AUTOSAR XML (schema 4-0-3)
package /ComponentTypes
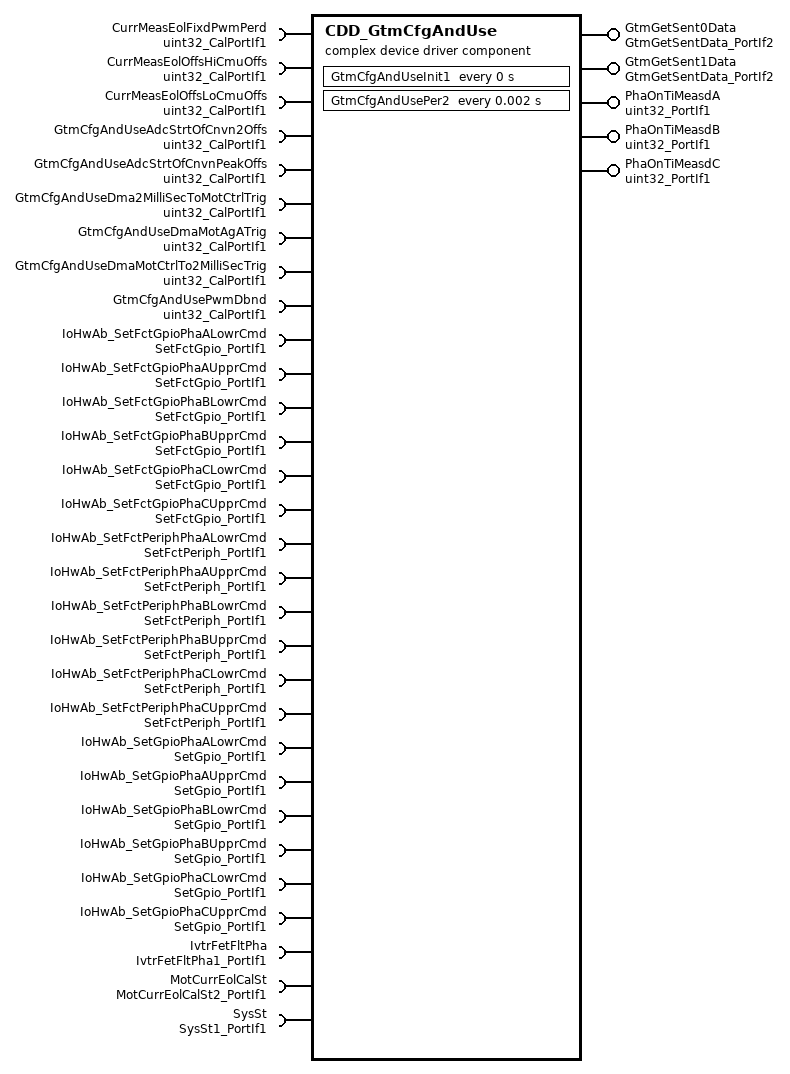
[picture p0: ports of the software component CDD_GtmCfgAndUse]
  complex device driver sw component type CDD_GtmCfgAndUse
    5 x provide port:
      GtmGetSent0Data: server-com-spec{operation=Oper, queue-length=1}, provided-interface=GtmGetSentData_PortIf2
      GtmGetSent1Data: server-com-spec{operation=Oper, queue-length=1}, provided-interface=GtmGetSentData_PortIf2
      PhaOnTiMeasdA: nonqueued-sender-com-spec{data-element=Val, init-value=0}, provided-interface=uint32_PortIf1
      PhaOnTiMeasdB: nonqueued-sender-com-spec{data-element=Val, init-value=0}, provided-interface=uint32_PortIf1
      PhaOnTiMeasdC: nonqueued-sender-com-spec{data-element=Val, init-value=0}, provided-interface=uint32_PortIf1
    30 x require port:
      CurrMeasEolFixdPwmPerd: parameter-require-com-spec{init-value=62500, parameter=Val}, required-interface=uint32_CalPortIf1
      CurrMeasEolOffsHiCmuOffs: parameter-require-com-spec{init-value=50000, parameter=Val}, required-interface=uint32_CalPortIf1
      CurrMeasEolOffsLoCmuOffs: parameter-require-com-spec{init-value=6250, parameter=Val}, required-interface=uint32_CalPortIf1
      GtmCfgAndUseAdcStrtOfCnvn2Offs: parameter-require-com-spec{init-value=25000, parameter=Val}, required-interface=uint32_CalPortIf1
      GtmCfgAndUseAdcStrtOfCnvnPeakOffs: parameter-require-com-spec{init-value=5000, parameter=Val}, required-interface=uint32_CalPortIf1
      GtmCfgAndUseDma2MilliSecToMotCtrlTrig: parameter-require-com-spec{init-value=25000, parameter=Val}, required-interface=uint32_CalPortIf1
      GtmCfgAndUseDmaMotAgATrig: parameter-require-com-spec{init-value=25000, parameter=Val}, required-interface=uint32_CalPortIf1
      GtmCfgAndUseDmaMotCtrlTo2MilliSecTrig: parameter-require-com-spec{init-value=25000, parameter=Val}, required-interface=uint32_CalPortIf1
      GtmCfgAndUsePwmDbnd: parameter-require-com-spec{init-value=200, parameter=Val}, required-interface=uint32_CalPortIf1
      IoHwAb_SetFctGpioPhaALowrCmd: client-com-spec=Oper, required-interface=SetFctGpio_PortIf1
      IoHwAb_SetFctGpioPhaAUpprCmd: client-com-spec=Oper, required-interface=SetFctGpio_PortIf1
      IoHwAb_SetFctGpioPhaBLowrCmd: client-com-spec=Oper, required-interface=SetFctGpio_PortIf1
      IoHwAb_SetFctGpioPhaBUpprCmd: client-com-spec=Oper, required-interface=SetFctGpio_PortIf1
      IoHwAb_SetFctGpioPhaCLowrCmd: client-com-spec=Oper, required-interface=SetFctGpio_PortIf1
      IoHwAb_SetFctGpioPhaCUpprCmd: client-com-spec=Oper, required-interface=SetFctGpio_PortIf1
      IoHwAb_SetFctPeriphPhaALowrCmd: client-com-spec=Oper, required-interface=SetFctPeriph_PortIf1
      IoHwAb_SetFctPeriphPhaAUpprCmd: client-com-spec=Oper, required-interface=SetFctPeriph_PortIf1
      IoHwAb_SetFctPeriphPhaBLowrCmd: client-com-spec=Oper, required-interface=SetFctPeriph_PortIf1
      IoHwAb_SetFctPeriphPhaBUpprCmd: client-com-spec=Oper, required-interface=SetFctPeriph_PortIf1
      IoHwAb_SetFctPeriphPhaCLowrCmd: client-com-spec=Oper, required-interface=SetFctPeriph_PortIf1
      IoHwAb_SetFctPeriphPhaCUpprCmd: client-com-spec=Oper, required-interface=SetFctPeriph_PortIf1
      IoHwAb_SetGpioPhaALowrCmd: client-com-spec=Oper, required-interface=SetGpio_PortIf1
      IoHwAb_SetGpioPhaAUpprCmd: client-com-spec=Oper, required-interface=SetGpio_PortIf1
      IoHwAb_SetGpioPhaBLowrCmd: client-com-spec=Oper, required-interface=SetGpio_PortIf1
      IoHwAb_SetGpioPhaBUpprCmd: client-com-spec=Oper, required-interface=SetGpio_PortIf1
      IoHwAb_SetGpioPhaCLowrCmd: client-com-spec=Oper, required-interface=SetGpio_PortIf1
      IoHwAb_SetGpioPhaCUpprCmd: client-com-spec=Oper, required-interface=SetGpio_PortIf1
      IvtrFetFltPha: nonqueued-receiver-com-spec{data-element=Val, filter=data-filter-type=ALWAYS, init-value=0}, required-interface=IvtrFetFltPha1_PortIf1
      MotCurrEolCalSt: nonqueued-receiver-com-spec{data-element=Val, filter=data-filter-type=ALWAYS, init-value=0}, required-interface=MotCurrEolCalSt2_PortIf1
      SysSt: nonqueued-receiver-com-spec{data-element=Val, filter=data-filter-type=ALWAYS, init-value=3}, required-interface=SysSt1_PortIf1
    behavior CDD_GtmCfgAndUse_InternalBehavior
      ar-typed-per-instance-memorys:
        14 x data, all with sw-calibration-access=READ-ONLY:
          AdcStrtOfCnvn2: type=uint32
          AdcStrtOfCnvnPeak: type=uint32
          Dma2MilliSecToMotCtrlTrig: type=uint32
          DmaMotAgATrig: type=uint32
          DmaMotCtrlTo2MilliSecTrig: type=uint32
          MissUpdCntr: type=uint16
          MissUpdIninCntr: type=uint8
          PhaAFetFldSts: type=boolean
          PhaBFetFldSts: type=boolean
          PhaCFetFldSts: type=boolean
          PhaOnTiCntrAPrev: type=uint32
          PhaOnTiCntrBPrev: type=uint32
          PhaOnTiCntrCPrev: type=uint32
          SysStEnaPrev: type=boolean
      timing event CDD_GtmCfgAndUse_InitEvent: start-on-event=GtmCfgAndUseInit1, period=0
      timing event TMT_GtmCfgAndUsePer2: start-on-event=GtmCfgAndUsePer2, period=0.002
      operation invoked event OIT_GtmGetSent0Data_Oper_GtmGetSent0Data_Oper: start-on-event=GtmGetSent0Data_Oper, operation=GtmGetSent0Data.Oper
      operation invoked event OIT_GtmGetSent1Data_Oper_GtmGetSent1Data_Oper: start-on-event=GtmGetSent1Data_Oper, operation=GtmGetSent1Data.Oper
      4 x runnable:
        GtmCfgAndUseInit1
          12 x sync call, all with timeout=0:
            SC_IoHwAb_SetFctGpioPhaALowrCmd_Oper: operation=IoHwAb_SetFctGpioPhaALowrCmd.Oper
            SC_IoHwAb_SetFctGpioPhaAUpprCmd_Oper: operation=IoHwAb_SetFctGpioPhaAUpprCmd.Oper
            SC_IoHwAb_SetFctGpioPhaBLowrCmd_Oper: operation=IoHwAb_SetFctGpioPhaBLowrCmd.Oper
            SC_IoHwAb_SetFctGpioPhaBUpprCmd_Oper: operation=IoHwAb_SetFctGpioPhaBUpprCmd.Oper
            SC_IoHwAb_SetFctGpioPhaCLowrCmd_Oper: operation=IoHwAb_SetFctGpioPhaCLowrCmd.Oper
            SC_IoHwAb_SetFctGpioPhaCUpprCmd_Oper: operation=IoHwAb_SetFctGpioPhaCUpprCmd.Oper
            SC_IoHwAb_SetGpioPhaALowrCmd_Oper: operation=IoHwAb_SetGpioPhaALowrCmd.Oper
            SC_IoHwAb_SetGpioPhaAUpprCmd_Oper: operation=IoHwAb_SetGpioPhaAUpprCmd.Oper
            SC_IoHwAb_SetGpioPhaBLowrCmd_Oper: operation=IoHwAb_SetGpioPhaBLowrCmd.Oper
            SC_IoHwAb_SetGpioPhaBUpprCmd_Oper: operation=IoHwAb_SetGpioPhaBUpprCmd.Oper
            SC_IoHwAb_SetGpioPhaCLowrCmd_Oper: operation=IoHwAb_SetGpioPhaCLowrCmd.Oper
            SC_IoHwAb_SetGpioPhaCUpprCmd_Oper: operation=IoHwAb_SetGpioPhaCUpprCmd.Oper
        GtmCfgAndUsePer2
          data-receive-point-by-arguments:
            access REC_IvtrFetFltPha_Val: accessed-variable=IvtrFetFltPha.Val
            access REC_MotCurrEolCalSt_Val: accessed-variable=MotCurrEolCalSt.Val
            access REC_SysSt_Val: accessed-variable=SysSt.Val
          data-send-points:
            access SEND_PhaOnTiMeasdA_Val: accessed-variable=PhaOnTiMeasdA.Val
            access SEND_PhaOnTiMeasdB_Val: accessed-variable=PhaOnTiMeasdB.Val
            access SEND_PhaOnTiMeasdC_Val: accessed-variable=PhaOnTiMeasdC.Val
          18 x sync call, all with timeout=0:
            SC_IoHwAb_SetFctGpioPhaALowrCmd_Oper: operation=IoHwAb_SetFctGpioPhaALowrCmd.Oper
            SC_IoHwAb_SetFctGpioPhaAUpprCmd_Oper: operation=IoHwAb_SetFctGpioPhaAUpprCmd.Oper
            SC_IoHwAb_SetFctGpioPhaBLowrCmd_Oper: operation=IoHwAb_SetFctGpioPhaBLowrCmd.Oper
            SC_IoHwAb_SetFctGpioPhaBUpprCmd_Oper: operation=IoHwAb_SetFctGpioPhaBUpprCmd.Oper
            SC_IoHwAb_SetFctGpioPhaCLowrCmd_Oper: operation=IoHwAb_SetFctGpioPhaCLowrCmd.Oper
            SC_IoHwAb_SetFctGpioPhaCUpprCmd_Oper: operation=IoHwAb_SetFctGpioPhaCUpprCmd.Oper
            SC_IoHwAb_SetFctPeriphPhaALowrCmd_Oper: operation=IoHwAb_SetFctPeriphPhaALowrCmd.Oper
            SC_IoHwAb_SetFctPeriphPhaAUpprCmd_Oper: operation=IoHwAb_SetFctPeriphPhaAUpprCmd.Oper
            SC_IoHwAb_SetFctPeriphPhaBLowrCmd_Oper: operation=IoHwAb_SetFctPeriphPhaBLowrCmd.Oper
            SC_IoHwAb_SetFctPeriphPhaBUpprCmd_Oper: operation=IoHwAb_SetFctPeriphPhaBUpprCmd.Oper
            SC_IoHwAb_SetFctPeriphPhaCLowrCmd_Oper: operation=IoHwAb_SetFctPeriphPhaCLowrCmd.Oper
            SC_IoHwAb_SetFctPeriphPhaCUpprCmd_Oper: operation=IoHwAb_SetFctPeriphPhaCUpprCmd.Oper
            SC_IoHwAb_SetGpioPhaALowrCmd_Oper: operation=IoHwAb_SetGpioPhaALowrCmd.Oper
            SC_IoHwAb_SetGpioPhaAUpprCmd_Oper: operation=IoHwAb_SetGpioPhaAUpprCmd.Oper
            SC_IoHwAb_SetGpioPhaBLowrCmd_Oper: operation=IoHwAb_SetGpioPhaBLowrCmd.Oper
            SC_IoHwAb_SetGpioPhaBUpprCmd_Oper: operation=IoHwAb_SetGpioPhaBUpprCmd.Oper
            SC_IoHwAb_SetGpioPhaCLowrCmd_Oper: operation=IoHwAb_SetGpioPhaCLowrCmd.Oper
            SC_IoHwAb_SetGpioPhaCUpprCmd_Oper: operation=IoHwAb_SetGpioPhaCUpprCmd.Oper
        GtmGetSent0Data_Oper
        GtmGetSent1Data_Oper
  swc implementation CDD_GtmCfgAndUse_Implementation: behavior=CDD_GtmCfgAndUse_InternalBehavior
    code-descriptors:
      code Default: artifact-descriptors=autosar-engineering-object={short-label=Default, category=SWSRC}
